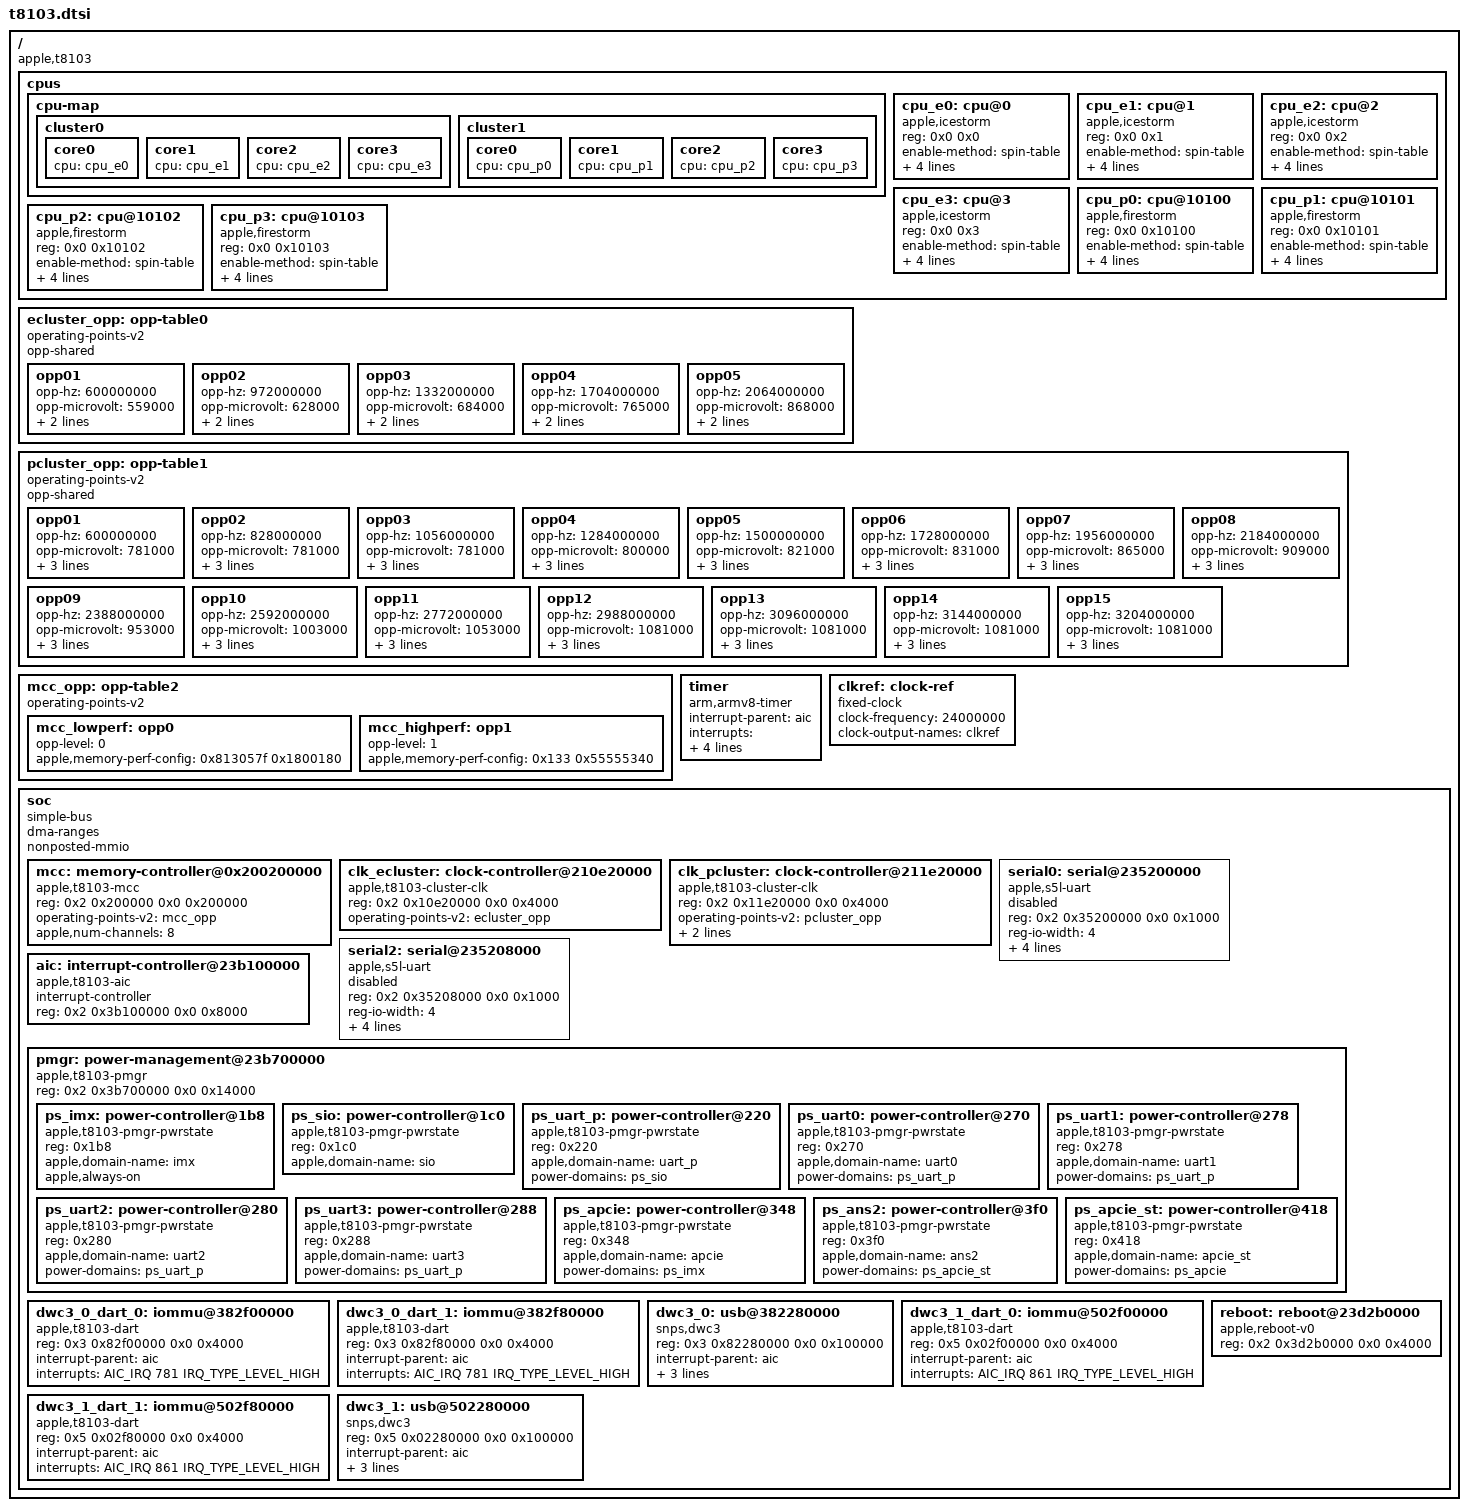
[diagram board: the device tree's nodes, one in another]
// SPDX-License-Identifier: GPL-2.0+ OR MIT
/*
 * Apple T8103 "M1" SoC
 *
 * Other names: H13G, "Tonga"
 *
 * Copyright The Asahi Linux Contributors
 */

#include <dt-bindings/interrupt-controller/apple-aic.h>
#include <dt-bindings/interrupt-controller/irq.h>

/ {
	compatible = "apple,t8103", "apple,arm-platform";

	#address-cells = <2>;
	#size-cells = <2>;

	cpus {
		#address-cells = <2>;
		#size-cells = <0>;

		cpu-map {
			cluster0 {
				core0 {
					cpu = <&cpu_e0>;
				};
				core1 {
					cpu = <&cpu_e1>;
				};
				core2 {
					cpu = <&cpu_e2>;
				};
				core3 {
					cpu = <&cpu_e3>;
				};
			};

			cluster1 {
				core0 {
					cpu = <&cpu_p0>;
				};
				core1 {
					cpu = <&cpu_p1>;
				};
				core2 {
					cpu = <&cpu_p2>;
				};
				core3 {
					cpu = <&cpu_p3>;
				};
			};
		};

		cpu_e0: cpu@0 {
			compatible = "apple,icestorm";
			device_type = "cpu";
			reg = <0x0 0x0>;
			enable-method = "spin-table";
			cpu-release-addr = <0 0>; /* To be filled by loader */
			clocks = <&clk_ecluster>;
			operating-points-v2 = <&ecluster_opp>;
			capacity-dmips-mhz = <714>;
		};

		cpu_e1: cpu@1 {
			compatible = "apple,icestorm";
			device_type = "cpu";
			reg = <0x0 0x1>;
			enable-method = "spin-table";
			cpu-release-addr = <0 0>; /* To be filled by loader */
			clocks = <&clk_ecluster>;
			operating-points-v2 = <&ecluster_opp>;
			capacity-dmips-mhz = <714>;
		};

		cpu_e2: cpu@2 {
			compatible = "apple,icestorm";
			device_type = "cpu";
			reg = <0x0 0x2>;
			enable-method = "spin-table";
			cpu-release-addr = <0 0>; /* To be filled by loader */
			clocks = <&clk_ecluster>;
			operating-points-v2 = <&ecluster_opp>;
			capacity-dmips-mhz = <714>;
		};

		cpu_e3: cpu@3 {
			compatible = "apple,icestorm";
			device_type = "cpu";
			reg = <0x0 0x3>;
			enable-method = "spin-table";
			cpu-release-addr = <0 0>; /* To be filled by loader */
			clocks = <&clk_ecluster>;
			operating-points-v2 = <&ecluster_opp>;
			capacity-dmips-mhz = <714>;
		};

		cpu_p0: cpu@10100 {
			compatible = "apple,firestorm";
			device_type = "cpu";
			reg = <0x0 0x10100>;
			enable-method = "spin-table";
			cpu-release-addr = <0 0>; /* To be filled by loader */
			clocks = <&clk_pcluster>;
			operating-points-v2 = <&pcluster_opp>;
			capacity-dmips-mhz = <1024>;
		};

		cpu_p1: cpu@10101 {
			compatible = "apple,firestorm";
			device_type = "cpu";
			reg = <0x0 0x10101>;
			enable-method = "spin-table";
			cpu-release-addr = <0 0>; /* To be filled by loader */
			clocks = <&clk_pcluster>;
			operating-points-v2 = <&pcluster_opp>;
			capacity-dmips-mhz = <1024>;
		};

		cpu_p2: cpu@10102 {
			compatible = "apple,firestorm";
			device_type = "cpu";
			reg = <0x0 0x10102>;
			enable-method = "spin-table";
			cpu-release-addr = <0 0>; /* To be filled by loader */
			clocks = <&clk_pcluster>;
			operating-points-v2 = <&pcluster_opp>;
			capacity-dmips-mhz = <1024>;
		};

		cpu_p3: cpu@10103 {
			compatible = "apple,firestorm";
			device_type = "cpu";
			reg = <0x0 0x10103>;
			enable-method = "spin-table";
			cpu-release-addr = <0 0>; /* To be filled by loader */
			clocks = <&clk_pcluster>;
			operating-points-v2 = <&pcluster_opp>;
			capacity-dmips-mhz = <1024>;
		};
	};

	ecluster_opp: opp-table0 {
		compatible = "operating-points-v2";
		opp-shared;

		opp01 {
			opp-hz = /bits/ 64 <600000000>;
			opp-microvolt = <559000>;
			opp-level = <1>;
			clock-latency-ns = <7500>;
		};
		opp02 {
			opp-hz = /bits/ 64 <972000000>;
			opp-microvolt = <628000>;
			opp-level = <2>;
			clock-latency-ns = <22000>;
		};
		opp03 {
			opp-hz = /bits/ 64 <1332000000>;
			opp-microvolt = <684000>;
			opp-level = <3>;
			clock-latency-ns = <27000>;
		};
		opp04 {
			opp-hz = /bits/ 64 <1704000000>;
			opp-microvolt = <765000>;
			opp-level = <4>;
			clock-latency-ns = <33000>;
		};
		opp05 {
			opp-hz = /bits/ 64 <2064000000>;
			opp-microvolt = <868000>;
			opp-level = <5>;
			clock-latency-ns = <50000>;
		};
	};

	pcluster_opp: opp-table1 {
		compatible = "operating-points-v2";
		opp-shared;

		opp01 {
			opp-hz = /bits/ 64 <600000000>;
			opp-microvolt = <781000>;
			opp-level = <1>;
			clock-latency-ns = <8000>;
			required-opps = <&mcc_lowperf>;
		};
		opp02 {
			opp-hz = /bits/ 64 <828000000>;
			opp-microvolt = <781000>;
			opp-level = <2>;
			clock-latency-ns = <19000>;
			required-opps = <&mcc_lowperf>;
		};
		opp03 {
			opp-hz = /bits/ 64 <1056000000>;
			opp-microvolt = <781000>;
			opp-level = <3>;
			clock-latency-ns = <21000>;
			required-opps = <&mcc_lowperf>;
		};
		opp04 {
			opp-hz = /bits/ 64 <1284000000>;
			opp-microvolt = <800000>;
			opp-level = <4>;
			clock-latency-ns = <23000>;
			required-opps = <&mcc_lowperf>;
		};
		opp05 {
			opp-hz = /bits/ 64 <1500000000>;
			opp-microvolt = <821000>;
			opp-level = <5>;
			clock-latency-ns = <24000>;
			required-opps = <&mcc_lowperf>;
		};
		opp06 {
			opp-hz = /bits/ 64 <1728000000>;
			opp-microvolt = <831000>;
			opp-level = <6>;
			clock-latency-ns = <29000>;
			required-opps = <&mcc_lowperf>;
		};
		opp07 {
			opp-hz = /bits/ 64 <1956000000>;
			opp-microvolt = <865000>;
			opp-level = <7>;
			clock-latency-ns = <31000>;
			required-opps = <&mcc_lowperf>;
		};
		opp08 {
			opp-hz = /bits/ 64 <2184000000>;
			opp-microvolt = <909000>;
			opp-level = <8>;
			clock-latency-ns = <34000>;
			required-opps = <&mcc_highperf>;
		};
		opp09 {
			opp-hz = /bits/ 64 <2388000000>;
			opp-microvolt = <953000>;
			opp-level = <9>;
			clock-latency-ns = <36000>;
			required-opps = <&mcc_highperf>;
		};
		opp10 {
			opp-hz = /bits/ 64 <2592000000>;
			opp-microvolt = <1003000>;
			opp-level = <10>;
			clock-latency-ns = <51000>;
			required-opps = <&mcc_highperf>;
		};
		opp11 {
			opp-hz = /bits/ 64 <2772000000>;
			opp-microvolt = <1053000>;
			opp-level = <11>;
			clock-latency-ns = <54000>;
			required-opps = <&mcc_highperf>;
		};
		opp12 {
			opp-hz = /bits/ 64 <2988000000>;
			opp-microvolt = <1081000>;
			opp-level = <12>;
			clock-latency-ns = <55000>;
			required-opps = <&mcc_highperf>;
		};
		opp13 {
			opp-hz = /bits/ 64 <3096000000>;
			opp-microvolt = <1081000>;
			opp-level = <13>;
			clock-latency-ns = <55000>;
			required-opps = <&mcc_highperf>;
		};
		opp14 {
			opp-hz = /bits/ 64 <3144000000>;
			opp-microvolt = <1081000>;
			opp-level = <14>;
			clock-latency-ns = <56000>;
			required-opps = <&mcc_highperf>;
		};
		opp15 {
			opp-hz = /bits/ 64 <3204000000>;
			opp-microvolt = <1081000>;
			opp-level = <15>;
			clock-latency-ns = <56000>;
			required-opps = <&mcc_highperf>;
		};
	};

	mcc_opp: opp-table2 {
		compatible = "operating-points-v2";

		mcc_lowperf: opp0 {
			opp-level = <0>;
			apple,memory-perf-config = <0x813057f 0x1800180>;
		};
		mcc_highperf: opp1 {
			opp-level = <1>;
			apple,memory-perf-config = <0x133 0x55555340>;
		};
	};

	timer {
		compatible = "arm,armv8-timer";
		interrupt-parent = <&aic>;
		interrupt-names = "phys", "virt", "hyp-phys", "hyp-virt";
		interrupts = <AIC_FIQ AIC_TMR_GUEST_PHYS IRQ_TYPE_LEVEL_HIGH>,
			     <AIC_FIQ AIC_TMR_GUEST_VIRT IRQ_TYPE_LEVEL_HIGH>,
			     <AIC_FIQ AIC_TMR_HV_PHYS IRQ_TYPE_LEVEL_HIGH>,
			     <AIC_FIQ AIC_TMR_HV_VIRT IRQ_TYPE_LEVEL_HIGH>;
	};

	clkref: clock-ref {
		compatible = "fixed-clock";
		#clock-cells = <0>;
		clock-frequency = <24000000>;
		clock-output-names = "clkref";
	};

	soc {
		compatible = "simple-bus";
		#address-cells = <2>;
		#size-cells = <2>;

		ranges;
		dma-ranges;
		nonposted-mmio;

		mcc: memory-controller@0x200200000 {
			compatible = "apple,t8103-mcc", "apple,mcc";
			#power-domain-cells = <0>;
			reg = <0x2 0x200000 0x0 0x200000>;
			operating-points-v2 = <&mcc_opp>;
			apple,num-channels = <8>;
		};

		clk_ecluster: clock-controller@210e20000 {
			compatible = "apple,t8103-cluster-clk", "apple,cluster-clk";
			#clock-cells = <0>;
			reg = <0x2 0x10e20000 0x0 0x4000>;
			operating-points-v2 = <&ecluster_opp>;
		};

		clk_pcluster: clock-controller@211e20000 {
			compatible = "apple,t8103-cluster-clk", "apple,cluster-clk";
			#clock-cells = <0>;
			reg = <0x2 0x11e20000 0x0 0x4000>;
			operating-points-v2 = <&pcluster_opp>;
			apple,dvmr;
			power-domains = <&mcc>;
		};

		serial0: serial@235200000 {
			compatible = "apple,s5l-uart";
			reg = <0x2 0x35200000 0x0 0x1000>;
			reg-io-width = <4>;
			interrupt-parent = <&aic>;
			interrupts = <AIC_IRQ 605 IRQ_TYPE_LEVEL_HIGH>;
			clocks = <&clkref>, <&clkref>, <&clkref>;
			clock-names = "uart", "clk_uart_baud0", "clk_uart_baud1";
			power-domains = <&ps_uart0>;
			status = "disabled";
		};

		serial2: serial@235208000 {
			compatible = "apple,s5l-uart";
			reg = <0x2 0x35208000 0x0 0x1000>;
			reg-io-width = <4>;
			interrupt-parent = <&aic>;
			interrupts = <AIC_IRQ 607 IRQ_TYPE_LEVEL_HIGH>;
			clocks = <&clkref>, <&clkref>, <&clkref>;
			clock-names = "uart", "clk_uart_baud0", "clk_uart_baud1";
			power-domains = <&ps_uart2>;
			status = "disabled";
		};

		aic: interrupt-controller@23b100000 {
			compatible = "apple,t8103-aic", "apple,aic";
			#interrupt-cells = <3>;
			interrupt-controller;
			reg = <0x2 0x3b100000 0x0 0x8000>;
		};

		pmgr: power-management@23b700000 {
			compatible = "apple,t8103-pmgr", "apple,pmgr", "syscon", "simple-mfd";
			#address-cells = <1>;
			#size-cells = <0>;

			reg = <0x2 0x3b700000 0x0 0x14000>;

			ps_imx: power-controller@1b8 {
				compatible = "apple,t8103-pmgr-pwrstate", "apple,pmgr-pwrstate";
				reg = <0x1b8>;
				#power-domain-cells = <0>;
				#reset-cells = <0>;
				apple,domain-name = "imx";
				apple,always-on;
			};

			ps_sio: power-controller@1c0 {
				compatible = "apple,t8103-pmgr-pwrstate", "apple,pmgr-pwrstate";
				reg = <0x1c0>;
				#power-domain-cells = <0>;
				#reset-cells = <0>;
				apple,domain-name = "sio";
			};

			ps_uart_p: power-controller@220 {
				compatible = "apple,t8103-pmgr-pwrstate", "apple,pmgr-pwrstate";
				reg = <0x220>;
				#power-domain-cells = <0>;
				#reset-cells = <0>;
				apple,domain-name = "uart_p";
				power-domains = <&ps_sio>;
			};

			ps_uart0: power-controller@270 {
				compatible = "apple,t8103-pmgr-pwrstate", "apple,pmgr-pwrstate";
				reg = <0x270>;
				#power-domain-cells = <0>;
				#reset-cells = <0>;
				apple,domain-name = "uart0";
				power-domains = <&ps_uart_p>;
			};

			ps_uart1: power-controller@278 {
				compatible = "apple,t8103-pmgr-pwrstate", "apple,pmgr-pwrstate";
				reg = <0x278>;
				#power-domain-cells = <0>;
				#reset-cells = <0>;
				apple,domain-name = "uart1";
				power-domains = <&ps_uart_p>;
			};

			ps_uart2: power-controller@280 {
				compatible = "apple,t8103-pmgr-pwrstate", "apple,pmgr-pwrstate";
				reg = <0x280>;
				#power-domain-cells = <0>;
				#reset-cells = <0>;
				apple,domain-name = "uart2";
				power-domains = <&ps_uart_p>;
			};

			ps_uart3: power-controller@288 {
				compatible = "apple,t8103-pmgr-pwrstate", "apple,pmgr-pwrstate";
				reg = <0x288>;
				#power-domain-cells = <0>;
				#reset-cells = <0>;
				apple,domain-name = "uart3";
				power-domains = <&ps_uart_p>;
			};

			ps_apcie: power-controller@348 {
				compatible = "apple,t8103-pmgr-pwrstate", "apple,pmgr-pwrstate";
				reg = <0x348>;
				#power-domain-cells = <0>;
				#reset-cells = <0>;
				apple,domain-name = "apcie";
				power-domains = <&ps_imx>;
			};

			ps_ans2: power-controller@3f0 {
				compatible = "apple,t8103-pmgr-pwrstate", "apple,pmgr-pwrstate";
				reg = <0x3f0>;
				#power-domain-cells = <0>;
				#reset-cells = <0>;
				apple,domain-name = "ans2";
				power-domains = <&ps_apcie_st>;
			};

			ps_apcie_st: power-controller@418 {
				compatible = "apple,t8103-pmgr-pwrstate", "apple,pmgr-pwrstate";
				reg = <0x418>;
				#power-domain-cells = <0>;
				#reset-cells = <0>;
				apple,domain-name = "apcie_st";
				power-domains = <&ps_apcie>;
			};
		};

		dwc3_0_dart_0: iommu@382f00000 {
			compatible = "apple,t8103-dart";
			reg = <0x3 0x82f00000 0x0 0x4000>;
			interrupt-parent = <&aic>;
			interrupts = <AIC_IRQ 781 IRQ_TYPE_LEVEL_HIGH>;
			#iommu-cells = <1>;
		};

		dwc3_0_dart_1: iommu@382f80000 {
			compatible = "apple,t8103-dart";
			reg = <0x3 0x82f80000 0x0 0x4000>;
			interrupt-parent = <&aic>;
			interrupts = <AIC_IRQ 781 IRQ_TYPE_LEVEL_HIGH>;
			#iommu-cells = <1>;
		};

		dwc3_0: usb@382280000{
			compatible = "snps,dwc3";
			reg = <0x3 0x82280000 0x0 0x100000>;
			interrupt-parent = <&aic>;
			interrupts = <AIC_IRQ 777 IRQ_TYPE_LEVEL_HIGH>;
			dr_mode = "host";
			iommus = <&dwc3_0_dart_0 0>, <&dwc3_0_dart_1 1>;
		};

		dwc3_1_dart_0: iommu@502f00000 {
			compatible = "apple,t8103-dart";
			reg = <0x5 0x02f00000 0x0 0x4000>;
			interrupt-parent = <&aic>;
			interrupts = <AIC_IRQ 861 IRQ_TYPE_LEVEL_HIGH>;
			#iommu-cells = <1>;
		};

		dwc3_1_dart_1: iommu@502f80000 {
			compatible = "apple,t8103-dart";
			reg = <0x5 0x02f80000 0x0 0x4000>;
			interrupt-parent = <&aic>;
			interrupts = <AIC_IRQ 861 IRQ_TYPE_LEVEL_HIGH>;
			#iommu-cells = <1>;
		};

		dwc3_1: usb@502280000{
			compatible = "snps,dwc3";
			reg = <0x5 0x02280000 0x0 0x100000>;
			interrupt-parent = <&aic>;
			interrupts = <AIC_IRQ 857 IRQ_TYPE_LEVEL_HIGH>;
			dr_mode = "host";
			iommus = <&dwc3_1_dart_0 0>, <&dwc3_1_dart_1 1>;
		};

		reboot: reboot@23d2b0000 {
			compatible = "apple,reboot-v0";
			reg = <0x2 0x3d2b0000 0x0 0x4000>;
		};
        };
};
